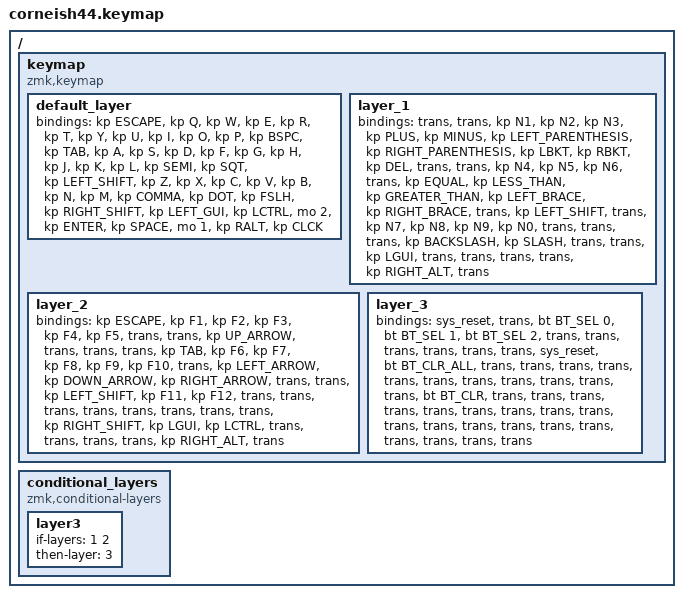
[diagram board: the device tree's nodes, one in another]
#include <behaviors.dtsi>
#include <dt-bindings/zmk/bt.h>
#include <dt-bindings/zmk/keys.h>

/ {
    keymap {
        compatible = "zmk,keymap";

        default_layer {
            // -----------------------------------------------------------------------------------------
            // |  TAB |  Q  |  W  |  E  |  R  |  T  |   |  Y  |  U   |  I  |  O  |  P  | BSPC |
            // | CTRL |  A  |  S  |  D  |  F  |  G  |   |  H  |  J   |  K  |  L  |  ;  |  '   |
            // | SHFT |  Z  |  X  |  C  |  V  |  B  |   |  N  |  M   |  ,  |  .  |  /  | ESC  |
            //                    | GUI | LWR | SPC |   | ENT | RSE  | ALT |

            bindings = <
&kp ESCAPE  &kp Q  &kp W  &kp E  &kp R  &kp T  &kp Y  &kp U  &kp I  &kp O  &kp P  &kp BSPC  &kp TAB  &kp A  &kp S  &kp D  &kp F  &kp G  &kp H  &kp J  &kp K  &kp L  &kp SEMI  &kp SQT  &kp LEFT_SHIFT  &kp Z  &kp X  &kp C  &kp V  &kp B  &kp N  &kp M  &kp COMMA  &kp DOT  &kp FSLH  &kp RIGHT_SHIFT  &kp LEFT_GUI  &kp LCTRL  &mo 2  &kp ENTER  &kp SPACE  &mo 1  &kp RALT  &kp CLCK
            >;
        };

        layer_1 {
            bindings = <
&trans  &trans  &kp N1  &kp N2  &kp N3  &kp PLUS  &kp MINUS  &kp LEFT_PARENTHESIS  &kp RIGHT_PARENTHESIS  &kp LBKT  &kp RBKT  &kp DEL  &trans  &trans  &kp N4  &kp N5  &kp N6  &trans  &kp EQUAL  &kp LESS_THAN  &kp GREATER_THAN  &kp LEFT_BRACE  &kp RIGHT_BRACE  &trans  &kp LEFT_SHIFT  &trans  &kp N7  &kp N8  &kp N9  &kp N0  &trans  &trans  &trans  &kp BACKSLASH  &kp SLASH  &trans  &trans  &kp LGUI  &trans  &trans  &trans  &trans  &kp RIGHT_ALT  &trans
            >;
        };

        layer_2 {
            bindings = <
&kp ESCAPE  &kp F1  &kp F2  &kp F3  &kp F4  &kp F5  &trans  &trans  &kp UP_ARROW  &trans  &trans  &trans  &kp TAB  &kp F6  &kp F7  &kp F8  &kp F9  &kp F10  &trans  &kp LEFT_ARROW  &kp DOWN_ARROW  &kp RIGHT_ARROW  &trans  &trans  &kp LEFT_SHIFT  &kp F11  &kp F12  &trans  &trans  &trans  &trans  &trans  &trans  &trans  &trans  &kp RIGHT_SHIFT  &kp LGUI  &kp LCTRL  &trans  &trans  &trans  &trans  &kp RIGHT_ALT  &trans
            >;
        };

        layer_3 {
            bindings = <
&sys_reset  &trans  &bt BT_SEL 0  &bt BT_SEL 1  &bt BT_SEL 2  &trans  &trans  &trans  &trans  &trans  &trans  &sys_reset  &bt BT_CLR_ALL  &trans  &trans  &trans  &trans  &trans  &trans  &trans  &trans  &trans  &trans  &trans  &bt BT_CLR  &trans  &trans  &trans  &trans  &trans  &trans  &trans  &trans  &trans  &trans  &trans  &trans  &trans  &trans  &trans  &trans  &trans  &trans  &trans
            >;
        };
    };

    conditional_layers {
        compatible = "zmk,conditional-layers";

        layer3 {
            if-layers = <1 2>;
            then-layer = <3>;
        };
    };
};
